# R7FA6M3AH register map
Vendor: Renesas; Series: RA6; File version: 1.2
CPU: CM4 r0p1, little endian, MPU, FPU, VTOR, 4 interrupt priority bits
Registers are 32-bit, read-write, reset 0x0 unless marked. A register's access mark holds for its fields unless they carry their own. Offsets are from the block's base; [hi:lo] are bit positions; {n}, {i} and the like mark numbered series; 'fields as' and 'values as' point back to an identical list; <NAME> marks a mode.

## SYSTEM — System Control
Base 0x4001E000
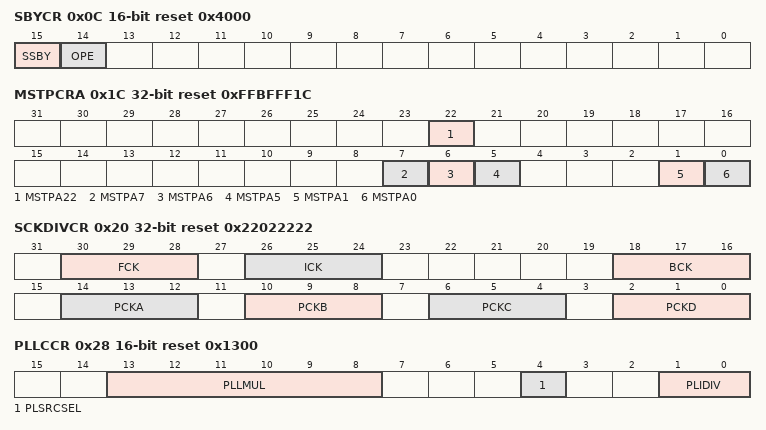
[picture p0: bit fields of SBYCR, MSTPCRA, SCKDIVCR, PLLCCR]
0x0C SBYCR 16-bit reset 0x4000 — Standby Control Register
  [15] SSBY — Software Standby
    0=Sleep mode; 1=Software Standby mode (DPSBYCR.DPSBY=0) / Deep Software Standby mode (DPSBYCR.DPSBY=1)
  [14] OPE — Output Port Enable
    0=In software standby mode or deep software standby mode, the address bus and bus control signals are set to the high-impedance state; 1=In software standby mode or deep software standby mode, the address bus and bus control signals retain the output state
0x1C MSTPCRA reset 0xFFBFFF1C — Module Stop Control Register A
  [all] fields
    0=Cancel the module-stop state; 1=Enter the module-stop state
  [22] MSTPA22 — DMA Controller/Data Transfer Controller Module Stop
  [7] MSTPA7 — Standny RAM Module Stop
  [6] MSTPA6 — ECCRAM Module Stop
  [5] MSTPA5 — High-Speed RAM Module Stop
  [1] MSTPA1 — RAM1 Module Stop
  [0] MSTPA0 — RAM0 Module Stop
0x20 SCKDIVCR reset 0x22022222 — System Clock Division Control Register
  [all] fields
    0=/1; 1=/2; 2=/4; 3=/8; 4=/16; 5=/32; 6=/64; other=others (Setting prohibited)
  [30:28] FCK — Flash IF Clock (FCLK) Select
  [26:24] ICK — System Clock (ICLK) Select
  [18:16] BCK — External Bus Clock (BCLK) Select
  [14:12] PCKA — Peripheral Module Clock A (PCLKA) Select
  [10:8] PCKB — Peripheral Module Clock B (PCLKB) Select
  [6:4] PCKC — Peripheral Module Clock C (PCLKC) Select
  [2:0] PCKD — Peripheral Module Clock D (PCLKD) Select
0x24 SCKDIVCR2 8-bit reset 0x40 — System Clock Division Control Register 2
  [6:4] UCK — USB Clock (UCLK) Select
    2=/3; 3=/4; 4=/5; other=others (Setting prohibited)
0x26 SCKSCR 8-bit reset 0x1 — System Clock Source Control Register
  [2:0] CKSEL — Clock Source Select
    0=HOCO; 1=MOCO; 2=LOCO; 3=Main clock oscillator; 4=Sub-clock oscillator; 5=PLL; other=others (Setting prohibited)
0x28 PLLCCR 16-bit reset 0x1300 — PLL Clock Control Register
  [13:8] PLLMUL range #010011..#111011 — PLL Frequency Multiplication Factor Select [PLL Frequency Multiplication Factor] = (PLLUMUL+1) / 2 Range: 0x23 - 0x3B for example 010011: x10.0 010100: x10.5 010101: x11.0 : 011100: x14.5 011101: x15.0 011110: x15.5 : 111010: x29.5 111011: x30.0
    other=others (Setting prohibited)
  [4] PLSRCSEL — PLL Clock Source Select
    0=Main clock oscillator; 1=HOCO
  [1:0] PLIDIV — PLL Input Frequency Division Ratio Select
    0=/1; 1=/2; 2=/3; 3=Setting prohibited
0x2A PLLCR 8-bit reset 0x1 — PLL Control Register
  [0] PLLSTP — PLL Stop Control
    0=Operate the PLL; 1=Stop the PLL
0x30 BCKCR 8-bit — External Bus Clock Control Register
  [0] BCLKDIV — BCLK Pin Output Select
    0=BCLK; 1=BCLK/2
0x32 MOSCCR 8-bit reset 0x1 — Main Clock Oscillator Control Register
  [0] MOSTP — Main Clock Oscillator Stop
    0=Main clock oscillator is operating; 1=Main clock oscillator is stopped
0x36 HOCOCR 8-bit (reset mask 0xFE) — High-Speed On-Chip Oscillator Control Register
  [0] HCSTP — HOCO Stop
    0=Operate the HOCO clock; 1=Stop the HOCO clock
0x38 MOCOCR 8-bit — Middle-Speed On-Chip Oscillator Control Register
  [0] MCSTP — MOCO Stop
    0=Operate the MOCO clock; 1=Stop the MOCO clock
0x39 FLLCR1 8-bit — FLL Control Register 1
  [0] FLLEN — FLL Enable
    0=FLL function is disabled; 1=FLL function is enabled
0x3A FLLCR2 16-bit — FLL Control Register 2
  [10:0] FLLCNTL — FLL Multiplication ControlMultiplication ratio of the FLL reference clock select
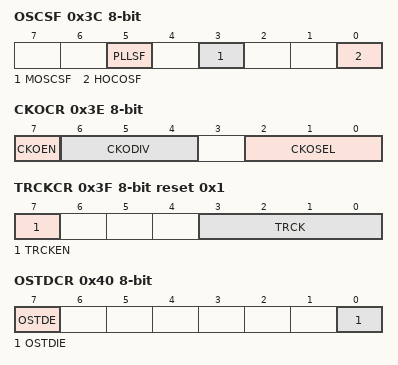
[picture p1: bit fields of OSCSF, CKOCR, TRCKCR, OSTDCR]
0x3C OSCSF 8-bit ro (reset mask 0xFE) — Oscillation Stabilization Flag Register
  [5] PLLSF — PLL Clock Oscillation Stabilization Flag
    0=PLL clock is stopped or is not yet stable; 1=PLL clock is stable, so is available for use as the system clock
  [3] MOSCSF — Main Clock Oscillation Stabilization Flag
    0=Main clock oscillator is stopped (MOSTP = 1) or is not yet stable; 1=Main clock oscillator is stable, so is available for use as the system clock
  [0] HOCOSF — HOCO Clock Oscillation Stabilization FlagNOTE: The HOCOSF bit value after a reset is 1 when the OFS1.HOCOEN bit is 0. It is 0 when the OFS1.HOCOEN bit is 1.
    0=HOCO clock is stopped or is not yet stable; 1=HOCO clock is stable, so is available for use as the system clock
0x3E CKOCR 8-bit — Clock Out Control Register
  [7] CKOEN — Clock out enable
    0=Disable clock out; 1=Enable clock out
  [6:4] CKODIV — Clock out input frequency Division Select
    0=/1; 1=/2; 2=/4; 3=/8; 4=/16; 5=/32; 6=/64; 7=/128
  [2:0] CKOSEL — Clock out source select
    0=HOCO; 1=MOCO; 2=LOCO; 3=MOSC; 4=SOSC; other=others (Setting prohibited)
0x3F TRCKCR 8-bit reset 0x1 — Trace Clock Control Register
  [7] TRCKEN — Trace Clock operating Enable
    0=Disable operation; 1=Enable operation
  [3:0] TRCK — Trace Clock operating frequency select
    0=/1; 1=/2; 2=/4; other=others (Setting prohibited)
0x40 OSTDCR 8-bit — Oscillation Stop Detection Control Register
  [7] OSTDE — Oscillation Stop Detection Function Enable
    0=Disable oscillation stop detection function; 1=Enable oscillation stop detection function
  [0] OSTDIE — Oscillation Stop Detection Interrupt Enable
    0=Disable oscillation stop detection interrupt (do not notify the POEG); 1=Enable oscillation stop detection interrupt (notify the POEG)
0x41 OSTDSR 8-bit — Oscillation Stop Detection Status Register
  [0] OSTDF write-0-clears read-modifies — Oscillation Stop Detection Flag
    0=Main clock oscillation stop not detected; 1=Main clock oscillation stop detected
0x52 EBCKOCR 8-bit — External Bus Clock Output Control Register
  [0] EBCKOEN — BCLK Pin Output Control
    0=Disable EBCLK pin output (fixed high); 1=Enable EBCLK pin output
0x53 SDCKOCR 8-bit — SDRAM Clock Output Control Register
  [0] SDCKOEN — SDCLK Pin Output Control
    0=Disable SDCLK pin output (fixed high); 1=Enable SDCLK pin output
0x61 MOCOUTCR 8-bit — MOCO User Trimming Control Register
  [7:0] MOCOUTRM — MOCO User Trimming 1000_0000 : -128 1000_0001 : -127 1000_0010 : -126 . . . 1111_1111 : -1 0000_0000 : Center Code 0000_0001 : +1 . . . 0111_1101 : +125 0111_1110 : +126 0111_1111 : +127These bits are added to original MOCO trimming bits
0x62 HOCOUTCR 8-bit — HOCO User Trimming Control Register
  [7:0] HOCOUTRM — HOCO User Trimming 1000_0000 : -128 1000_0001 : -127 1000_0010 : -126 . . . 1111_1111 : -1 0000_0000 : Center Code 0000_0001 : +1 . . . 0111_1101 : +125 0111_1110 : +126 0111_1111 : +127These bits are added to original HOCO trimming bits
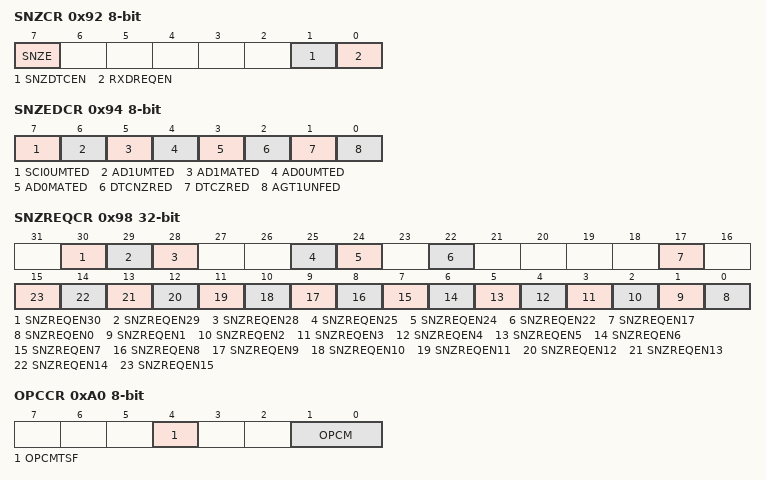
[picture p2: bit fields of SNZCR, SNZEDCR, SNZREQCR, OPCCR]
0x92 SNZCR 8-bit — Snooze Control Register
  [7] SNZE — Snooze Mode Enable
    0=Disable Snooze Mode; 1=Enable Snooze Mode
  [1] SNZDTCEN — DTC Enable in Snooze Mode
    0=Disable DTC operation; 1=Enable DTC operation
  [0] RXDREQEN — RXD0 Snooze Request Enable NOTE: Do not set to 1 other than in asynchronous mode.
    0=Ignore RXD0 falling edge in Standby mode; 1=Accept RXD0 falling edge in Standby mode as a request to transit to Snooze mode
0x94 SNZEDCR 8-bit — Snooze End Control Register
  [all] fields
    0=Disable the Snooze End request; 1=Enable the Snooze End request
  [7] SCI0UMTED — SCI0 address unmatch Snooze End EnableNote: Do not set to 1 other than in asynchronous mode.
  [6] AD1UMTED — AD compare mismatch 1 Snooze End Enable
  [5] AD1MATED — AD compare match 1 Snooze End Enable
  [4] AD0UMTED — AD compare mismatch 0 Snooze End Enable
  [3] AD0MATED — AD compare match 0 Snooze End Enable
  [2] DTCNZRED — Not Last DTC transmission completion Snooze End Enable
  [1] DTCZRED — Last DTC transmission completion Snooze End Enable
  [0] AGT1UNFED — AGT1 underflow Snooze End Enable
0x98 SNZREQCR — Snooze Request Control Register
  [all] fields
    0=Disable snooze request; 1=Enable snooze request
  [30] SNZREQEN30 — Snooze Request Enable 30Enable AGT1 compare match B snooze request
  [29] SNZREQEN29 — Snooze Request Enable 29Enable AGT1 compare match A snooze request
  [28] SNZREQEN28 — Snooze Request Enable 28Enable AGT1 underflow snooze request
  [25] SNZREQEN25 — Snooze Request Enable 25Enable RTC period snooze request
  [24] SNZREQEN24 — Snooze Request Enable 24Enable RTC alarm snooze request
  [22] SNZREQEN22 — Snooze Request Enable 22Enable Comparator-OC0 snooze request
  [17] SNZREQEN17 — Snooze Request Enable 17Enable KR snooze request
  [n] SNZREQEN{n} (n=0..15) — Snooze Request Enable {n}Enable IRQ{n} pin snooze request
0xA0 OPCCR 8-bit — Operating Power Control Register
  [4] OPCMTSF ro — Operating Power Control Mode Transition Status Flag
    0=Transition completed; 1=During transition
  [1:0] OPCM — Operating Power Control Mode Select
    0=High-speed mode; 1=Prohibited; 2=Prohibited; 3=Low-speed mode; other=others (Setting prohibited)
0xA2 MOSCWTCR 8-bit reset 0x5 — Main Clock Oscillator Wait Control Register
  [3:0] MSTS — Main clock oscillator wait time setting
    1=Wait time = 35 cycles (133.5 μs); 2=Wait time = 67 cycles (255.6 μs); 3=Wait time = 131 cycles (499.7 μs); 4=Wait time = 259 cycles (988.0 μs); 5=Wait time = 547 cycles (2086.6 μs) (value after reset); 6=Wait time = 1059 cycles (4039.8 μs); 7=Wait time = 2147 cycles (8190.2 μs); 8=Wait time = 4291 cycles (16368.9 μs); 9=Wait time = 8163 cycles (31139.4 μs); other=others (settings prohibited.)
0xA5 HOCOWTCR 8-bit reset 0x2 — High-speed on-chip oscillator wait control register
  [2:0] HSTS — HOCO wait time settingWaiting time (sec) = setting of the HSTS[2:0] bits/fLOCO(Trimmed) + 3/fLOC(Untrimmed)
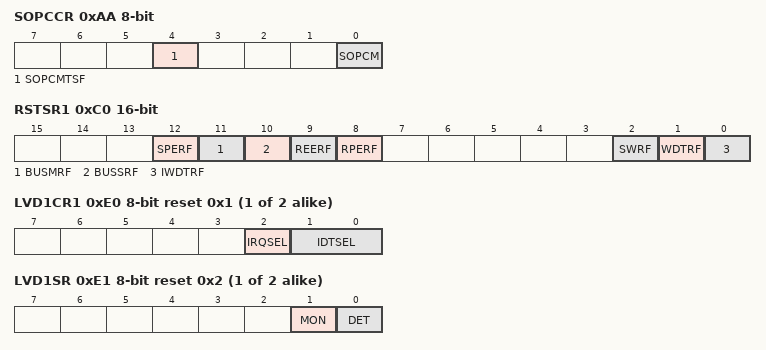
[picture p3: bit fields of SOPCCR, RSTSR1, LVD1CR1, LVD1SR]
0xAA SOPCCR 8-bit — Sub Operating Power Control Register
  [4] SOPCMTSF ro — Sub Operating Power Control Mode Transition Status Flag
    0=Transition completed; 1=During transition
  [0] SOPCM — Sub Operating Power Control Mode Select
    0=Other than Subosc-speed mode; 1=Subosc-speed mode
0xC0 RSTSR1 16-bit (reset mask 0xE0F8) — Reset Status Register 1
  [12] SPERF write-0-clears read-modifies — SP Error Reset Detect FlagNOTE: Writable only to clear the flag. Confirm the value is 1 and then write 0.
    0=SP error reset not detected; 1=SP error reset detected
  [11] BUSMRF write-0-clears read-modifies — Bus Master MPU Reset Detect FlagNOTE: Writable only to clear the flag. Confirm the value is 1 and then write 0.
    0=Bus Master MPU reset not detected; 1=Bus Master MPU reset detected
  [10] BUSSRF write-0-clears read-modifies — Bus Slave MPU Reset Detect FlagNOTE: Writable only to clear the flag. Confirm the value is 1 and then write 0.
    0=Bus Slave MPU reset not detected; 1=Bus Slave MPU reset detected
  [9] REERF write-0-clears read-modifies — RAM ECC Error Reset Detect FlagNOTE: Writable only to clear the flag. Confirm the value is 1 and then write 0.
    0=RAM ECC error reset not detected; 1=RAM ECC error reset detected
  [8] RPERF write-0-clears read-modifies — RAM Parity Error Reset Detect FlagNOTE: Writable only to clear the flag. Confirm the value is 1 and then write 0.
    0=RAM parity error reset not detected; 1=RAM parity error reset detected
  [2] SWRF write-0-clears read-modifies — Software Reset Detect FlagNOTE: Writable only to clear the flag. Confirm the value is 1 and then write 0.
    0=Software reset not detected; 1=Software reset detected
  [1] WDTRF write-0-clears read-modifies — Watchdog Timer Reset Detect FlagNOTE: Writable only to clear the flag. Confirm the value is 1 and then write 0.
    0=Watchdog timer reset not detected; 1=Watchdog timer reset detected
  [0] IWDTRF write-0-clears read-modifies — Independent Watchdog Timer Reset Detect FlagNOTE: Writable only to clear the flag. Confirm the value is 1 and then write 0.
    0=Independent watchdog timer reset not detected; 1=Independent watchdog timer reset detected
{0xDE+2i} LVD{i}CR1 (i=1..2) 8-bit reset 0x1 — Voltage Monitor {i} Circuit Control Register 1
  [2] IRQSEL — Voltage Monitor Interrupt Type Select
    0=Non-maskable interrupt; 1=Maskable interrupt
  [1:0] IDTSEL — Voltage Monitor Interrupt Generation Condition Select
    0=Generate when VCC>=Vdet (rise) is detected; 1=Generate when VCC<Vdet (drop) is detected; 2=Generate when drop and rise are detected; 3=Settings prohibited
{0xDF+2i} LVD{i}SR (i=1..2) 8-bit reset 0x2 — Voltage Monitor {i} Circuit Status Register
  [1] MON ro — Voltage Monitor 1 Signal Monitor Flag
    0=VCC < Vdet; 1=VCC >= Vdet or MON bit is disabled
  [0] DET write-0-clears read-modifies — Voltage Monitor Voltage Change Detection Flag NOTE: Only 0 can be written to this bit. After writing 0 to this bit, it takes 2 system clock cycles for the bit to be read as 0.
    0=Not detected; 1=Vdet1 passage detection
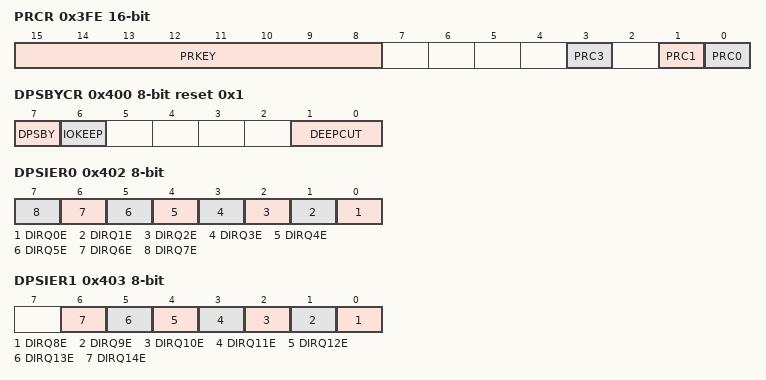
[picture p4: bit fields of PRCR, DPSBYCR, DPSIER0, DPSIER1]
0x3FE PRCR 16-bit — Protect Register
  [15:8] PRKEY wo — PRKEY Key Code
    90=Enables writing to the PRCR register; other=others (Disables writing to the PRCR register.)
  [3] PRC3 — Enables writing to the registers related to the LVD.
    0=Writes protected; 1=Writes not protected
  [1] PRC1 — Enables writing to the registers related to the operating modes, the low power consumption modes and the battery backup function.
    0=Writes protected; 1=Writes not protected
  [0] PRC0 — Enables writing to the registers related to the clock generation circuit.
    0=Writes protected; 1=Writes not protected
0x400 DPSBYCR 8-bit reset 0x1 — Deep Standby Control Register
  [7] DPSBY — Deep Software Standby
    0=Sleep mode (SBYCR.SSBY=0) / Software Standby mode (SBYCR.SSBY=1); 1=Sleep mode (SBYCR.SSBY=0) / Deep Software Standby mode (SBYCR.SSBY=1)
  [6] IOKEEP — I/O Port Retention
    0=When the Deep Software Standby mode is canceled, the I/O ports are in the reset state; 1=When the Deep Software Standby mode is canceled, the I/O ports are in the same state as in the Deep Software Standby mode
  [1:0] DEEPCUT — Power-Supply Control
    0=Power to the standby RAM, Low-speed on-chip oscillator, AGTn, and USBFS/HS resume detecting unit is supplied in deep software standby mode; 1=Power to the standby RAM, Low-speed on-chip oscillator, AGTn, and USBFS/HS resume detecting unit is not supplied in deep software standby mode; 2=Setting prohibited; 3=Power to the standby RAM, Low-speed on-chip oscillator, AGTn, and USBFS/HS resume detecting unit is supplied in deep software standby mode. In addition, LVD is disabled and the low power function in a power-on reset circuit is enabled.
0x402 DPSIER0 8-bit — Deep Standby Interrupt Enable Register 0
  [all] fields
    0=Canceling deep software standby mode is disabled; 1=Canceling deep software standby mode is enabled
  [n] DIRQ{n}E (n=0..7) — IRQ{n}-DS Pin Enable
0x403 DPSIER1 8-bit — Deep Standby Interrupt Enable Register 1
  [all] fields
    values as the fields of DPSIER0
  [n-8] DIRQ{n}E (n=8..14) — IRQ{n}-DS Pin Enable
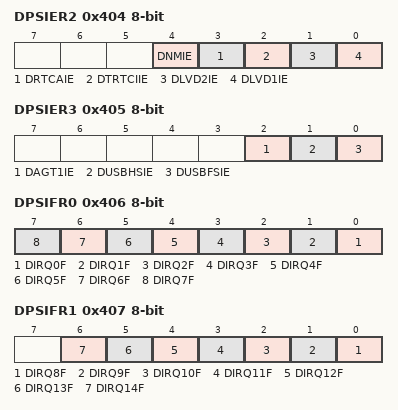
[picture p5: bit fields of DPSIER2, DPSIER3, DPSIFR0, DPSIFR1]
0x404 DPSIER2 8-bit — Deep Standby Interrupt Enable Register 2
  [all] fields
    values as the fields of DPSIER0
  [4] DNMIE — NMI Pin Enable
  [3] DRTCAIE — RTC Alarm interrupt Deep Standby Cancel Signal Enable
  [2] DTRTCIIE — RTC Interval interrupt Deep Standby Cancel Signal Enable
  [1] DLVD2IE — LVD2 Deep Standby Cancel Signal Enable
  [0] DLVD1IE — LVD1 Deep Standby Cancel Signal Enable
0x405 DPSIER3 8-bit — Deep Standby Interrupt Enable Register 3
  [all] fields
    values as the fields of DPSIER0
  [2] DAGT1IE — AGT1 Underflow Deep Standby Cancel Signal Enable
  [1] DUSBHSIE — USBHS Suspend/Resume Deep Standby Cancel Signal Enable
  [0] DUSBFSIE — USBFS Suspend/Resume Deep Standby Cancel Signal Enable
0x406 DPSIFR0 8-bit — Deep Standby Interrupt Flag Register 0
  [all] fields
    0=The cancel request is not generated; 1=The cancel request is generated
  [n] DIRQ{n}F write-0-clears read-modifies (n=0..7) — IRQ{n}-DS Pin Deep Standby Cancel Flag
0x407 DPSIFR1 8-bit — Deep Standby Interrupt Flag Register 1
  [all] fields
    values as the fields of DPSIFR0
  [n-8] DIRQ{n}F write-0-clears read-modifies (n=8..14) — IRQ{n}-DS Pin Deep Standby Cancel Flag
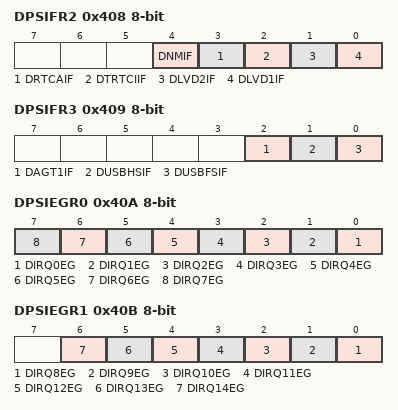
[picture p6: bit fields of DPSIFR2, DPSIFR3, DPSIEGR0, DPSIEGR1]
0x408 DPSIFR2 8-bit — Deep Standby Interrupt Flag Register 2
  [all] fields
    values as the fields of DPSIFR0
  [4] DNMIF write-0-clears read-modifies — NMI Pin Deep Standby Cancel Flag
  [3] DRTCAIF write-0-clears read-modifies — RTC Alarm interrupt Deep Standby Cancel Flag
  [2] DTRTCIIF write-0-clears read-modifies — RTC Interval interrupt Deep Standby Cancel Flag
  [1] DLVD2IF write-0-clears read-modifies — LVD2 Deep Standby Cancel Flag
  [0] DLVD1IF write-0-clears read-modifies — LVD1 Deep Standby Cancel Flag
0x409 DPSIFR3 8-bit — Deep Standby Interrupt Flag Register 3
  [all] fields
    values as the fields of DPSIFR0
  [2] DAGT1IF write-0-clears read-modifies — AGT1 Underflow Deep Standby Cancel Flag
  [1] DUSBHSIF write-0-clears read-modifies — USBHS Suspend/Resume Deep Standby Cancel Flag
  [0] DUSBFSIF write-0-clears read-modifies — USBFS Suspend/Resume Deep Standby Cancel Flag
0x40A DPSIEGR0 8-bit — Deep Standby Interrupt Edge Register 0
  [all] fields
    0=A cancel request is generated at a falling edge; 1=A cancel request is generated at a rising edge
  [n] DIRQ{n}EG (n=0..7) — IRQ{n}-DS Pin Edge Select
0x40B DPSIEGR1 8-bit — Deep Standby Interrupt Edge Register 1
  [all] fields
    values as the fields of DPSIEGR0
  [n-8] DIRQ{n}EG (n=8..14) — IRQ{n}-DS Pin Edge Select
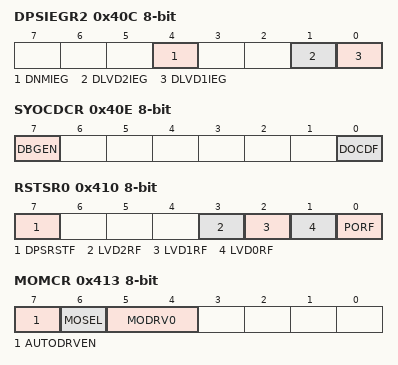
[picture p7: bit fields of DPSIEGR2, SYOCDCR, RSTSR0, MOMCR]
0x40C DPSIEGR2 8-bit — Deep Standby Interrupt Edge Register 2
  [4] DNMIEG — NMI Pin Edge Select
    values as the fields of DPSIEGR0
  [1] DLVD2IEG — LVD2 Edge Select
    0=A cancel request is generated when VCC<Vdet2 (fall) is detected; 1=A cancel request is generated when VCC>=Vdet2 (rise) is detected
  [0] DLVD1IEG — LVD1 Edge Select
    0=A cancel request is generated when VCC<Vdet1 (fall) is detected; 1=A cancel request is generated when VCC>=Vdet1 (rise) is detected
0x40E SYOCDCR 8-bit (reset mask 0xFE) — System Control OCD Control Register
  [7] DBGEN — Debugger Enable bit
    0=On-chip debugger is disabled; 1=On-chip debugger is enabled
  [0] DOCDF write-0-clears read-modifies — Deep Standby OCD flag
    values as DBGEN
0x40F STCONR 8-bit reset 0xC3 — Standby Condition Register
  [1:0] STCON — SSTBY condition bit
    0=set this value in case of transferring to Software Standby Mode in using HOCO; 3=set this value in case of transferring to Software Standby Mode in using expect for HOCO
0x410 RSTSR0 8-bit (reset mask 0x70) — Reset Status Register 0
  [7] DPSRSTF write-0-clears read-modifies — Deep Software Standby Reset FlagNOTE: Writable only to clear the flag. Confirm the value is 1 and then write 0.
    0=Deep software standby mode cancelation not requested by an interrupt; 1=Deep software standby mode cancelation requested by an interrupt
  [3] LVD2RF write-0-clears read-modifies — Voltage Monitor 2 Reset Detect FlagNOTE: Writable only to clear the flag. Confirm the value is 1 and then write 0.
    0=Voltage Monitor 2 reset not detected; 1=Voltage Monitor 2 reset detected
  [2] LVD1RF write-0-clears read-modifies — Voltage Monitor 1 Reset Detect FlagNOTE: Writable only to clear the flag. Confirm the value is 1 and then write 0.
    0=Voltage Monitor 1 reset not detected; 1=Voltage Monitor 1 reset detected
  [1] LVD0RF write-0-clears read-modifies — Voltage Monitor 0 Reset Detect FlagNOTE: Writable only to clear the flag. Confirm the value is 1 and then write 0.
    0=Voltage Monitor 0 reset not detected; 1=Voltage Monitor 0 reset detected
  [0] PORF write-0-clears read-modifies — Power-On Reset Detect FlagNOTE: Writable only to clear the flag. Confirm the value is 1 and then write 0.
    0=Power-on reset not detected; 1=Power-on reset detected
0x411 RSTSR2 8-bit (reset mask 0xFE) — Reset Status Register 2
  [0] CWSF write-1-sets read-modifies — Cold/Warm Start Determination Flag
    0=Cold start; 1=Warm start
0x413 MOMCR 8-bit — Main Clock Oscillator Mode Oscillation Control Register
  [7] AUTODRVEN — Main Clock Oscillator Drive Capability Auto Switching Enable
    0=Disable; 1=Enable
  [6] MOSEL — Main Clock Oscillator Switching
    0=Resonator; 1=External clock input
  [5:4] MODRV0 — Main Clock Oscillator Drive Capability 0 Switching
    0=20MHz to 24MHz; 1=16MHz to 20MHz; 2=8MHz to 16MHz; 3=8MHz
0x416 FWEPROR 8-bit reset 0x2 — Flash P/E Protect Register
  [1:0] FLWE — Flash Programming and Erasure
    0=Prohibits programming and erasure of the code flash, data flash or blank checking; 1=Permits programming and erasure of the code flash, data flash or blank checking; 2=Prohibits programming and erasure of the code flash, data flash or blank checking; 3=Prohibits programming and erasure of the code flash, data flash or blank checking
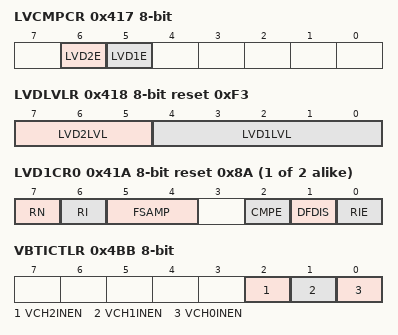
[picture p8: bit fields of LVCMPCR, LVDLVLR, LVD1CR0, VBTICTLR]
0x417 LVCMPCR 8-bit — Voltage Monitor Circuit Control Register
  [6] LVD2E — Voltage Detection 2 Enable
    0=Voltage detection 2 circuit disabled; 1=Voltage detection 2 circuit enabled
  [5] LVD1E — Voltage Detection 1 Enable
    0=Voltage detection 1 circuit disabled; 1=Voltage detection 1 circuit enabled
0x418 LVDLVLR 8-bit reset 0xF3 — Voltage Detection Level Select Register
  [7:5] LVD2LVL — Voltage Detection 2 Level Select (Standard voltage during fall in voltage)
    5=2.99V (Vdet2_1); 6=2.92V (Vdet2_2); 7=2.85V (Vdet2_3); other=others (Settings other than above are prohibited.)
  [4:0] LVD1LVL — Voltage Detection 1 Level Select (Standard voltage during fall in voltage)
    17=2.99V (Vdet1_1); 18=2.92V (Vdet1_2); 19=2.85V (Vdet1_3); other=others (Settings other than above are prohibited.)
{0x419+i} LVD{i}CR0 (i=1..2) 8-bit reset 0x8A — Voltage Monitor {i} Circuit Control Register 0
  [7] RN — Voltage Monitor Reset Negate Select
    0=Negation follows a stabilization time (tLVD) after VCC > Vdet is detected; 1=Negation follows a stabilization time (tLVD) after assertion of the LVD reset
  [6] RI — Voltage Monitor Circuit Mode Select
    0=Voltage Monitor interrupt during Vdet1 passage; 1=Voltage Monitor reset enabled when the voltage falls to and below Vdet1
  [5:4] FSAMP — Sampling Clock Select
    0=1/2 LOCO frequency; 1=1/4 LOCO frequency; 2=1/8 LOCO frequency; 3=1/16 LOCO frequency
  [2] CMPE — Voltage Monitor Circuit Comparison Result Output Enable
    0=Disable voltage monitor 1 circuit comparison result output; 1=Enable voltage monitor 1 circuit comparison result output
  [1] DFDIS — Voltage Monitor Digital Filter Disable Mode Select
    0=Enable digital filter; 1=Disable digital filter
  [0] RIE — Voltage Monitor Interrupt/Reset Enable
    0=Disable; 1=Enable
0x480 SOSCCR 8-bit — Sub-clock oscillator control register
  [0] SOSTP — Sub-Clock Oscillator Stop
    0=Operate the sub-clock oscillator; 1=Stop the sub-clock oscillator
0x481 SOMCR 8-bit (reset mask 0xFD) — Sub Clock Oscillator Mode Control Register
  [1] SODRV1 — Sub Clock Oscillator Drive Capability Switching
    0=Standard; 1=Middle
0x490 LOCOCR 8-bit — Low-Speed On-Chip Oscillator Control Register
  [0] LCSTP — LOCO Stop
    0=Operate the LOCO clock; 1=Stop the LOCO clock
0x492 LOCOUTCR 8-bit — LOCO User Trimming Control Register
  [7:0] LOCOUTRM — LOCO User Trimming 1000_0000 : -128 1000_0001 : -127 1000_0010 : -126 . . . 1111_1111 : -1 0000_0000 : Center Code 0000_0001 : +1 . . . 0111_1101 : +125 0111_1110 : +126 0111_1111 : +127These bits are added to original LOCO trimming bits
0x4BB VBTICTLR 8-bit (reset mask 0xF8) — VBATT Input Control Register
  [all] fields
    0=Disabled; 1=Enabled
  [2] VCH2INEN — RTCIC2 Input Enable
  [1] VCH1INEN — RTCIC1 Input Enable
  [0] VCH0INEN — RTCIC0 Input Enable
{0x500+i} VBTBKR[{i}] (i=0..511) 8-bit reset not defined — VBATT Backup Register [{i}]
  [7:0] VBTBKR — VBTBKR is a 512-byte readable/writable register to store data powered by VBATT.The value of this register is retained even when VCC is not powered but VBATT is powered.VBTBKR is initialized by VBATT selected voltage power-on-reset.
